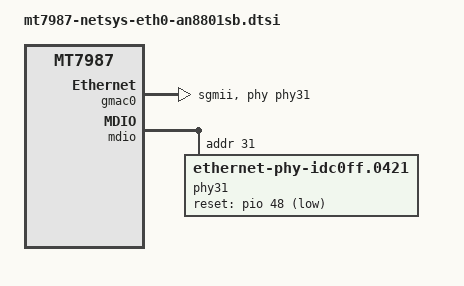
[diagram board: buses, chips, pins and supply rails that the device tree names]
// SPDX-License-Identifier: (GPL-2.0 OR MIT)

&eth {
	gmac0: mac@0 {
		compatible = "mediatek,eth-mac";
		reg = <0>;
		pcs-handle = <&sgmiipcs0>;
		phy-mode = "sgmii";
		phy-handle = <&phy31>;
	};
};

&mdio {
	phy31: phy@31 {
		compatible = "ethernet-phy-idc0ff.0421";
		reg = <31>;
		reset-gpios = <&pio 48 1>;
		reset-assert-us = <10000>;
		reset-deassert-us = <10000>;
		phy-mode = "sgmii";
		eee-broken-100tx;
		eee-broken-1000t;
	};
};

&hnat {
	mtketh-lan = "eth0";
};
